# SKEAZ1284 register map
Vendor: Freescale Semiconductor, Inc.; Series: Kinetis_EA; File version: 1.6
CPU: CM0PLUS r0p0, little endian, no MPU, no FPU, VTOR, 2 interrupt priority bits
Registers are 8-bit, read-write, reset 0x0 unless marked. A register's access mark holds for its fields unless they carry their own. Offsets are from the block's base; [hi:lo] are bit positions; {n}, {i} and the like mark numbered series.

## SystemControl — System Control Registers
Base 0xE000E000; register names take the prefix SCB_
0x08 ACTLR 32-bit ro — Auxiliary Control Register,
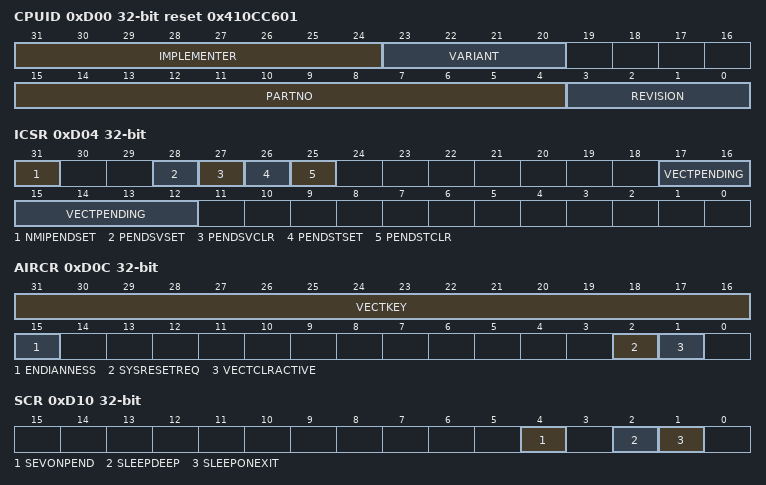
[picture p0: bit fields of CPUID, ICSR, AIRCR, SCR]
0xD00 CPUID 32-bit ro reset 0x410CC601 — CPUID Base Register
  [31:24] IMPLEMENTER — Implementer code
  [23:20] VARIANT — Indicates processor revision: 0x2 = Revision 2
  [15:4] PARTNO — Indicates part number
  [3:0] REVISION — Indicates patch release: 0x0 = Patch 0
0xD04 ICSR 32-bit — Interrupt Control and State Register
  [31] NMIPENDSET
    0=write: no effect; read: NMI exception is not pending; 1=write: changes NMI exception state to pending; read: NMI exception is pending
  [28] PENDSVSET
    0=write: no effect; read: PendSV exception is not pending; 1=write: changes PendSV exception state to pending; read: PendSV exception is pending
  [27] PENDSVCLR wo
    0=no effect; 1=removes the pending state from the PendSV exception
  [26] PENDSTSET
    0=write: no effect; read: SysTick exception is not pending; 1=write: changes SysTick exception state to pending; read: SysTick exception is pending
  [25] PENDSTCLR wo
    0=no effect; 1=removes the pending state from the SysTick exception
  [17:12] VECTPENDING ro — Exception number of the highest priority pending enabled exception
0xD08 VTOR 32-bit — Vector Table Offset Register
  [31:7] TBLOFF — Vector table base offset
0xD0C AIRCR 32-bit — Application Interrupt and Reset Control Register
  [31:16] VECTKEY — Register key
  [15] ENDIANNESS ro
    0=Little-endian; 1=Big-endian
  [2] SYSRESETREQ wo
    0=no system reset request; 1=asserts a signal to the outer system that requests a reset
  [1] VECTCLRACTIVE wo
0xD10 SCR 32-bit — System Control Register
  [4] SEVONPEND
    0=only enabled interrupts or events can wakeup the processor, disabled interrupts are excluded; 1=enabled events and all interrupts, including disabled interrupts, can wakeup the processor
  [2] SLEEPDEEP
    0=sleep; 1=deep sleep
  [1] SLEEPONEXIT
    0=do not sleep when returning to Thread mode; 1=enter sleep, or deep sleep, on return from an ISR
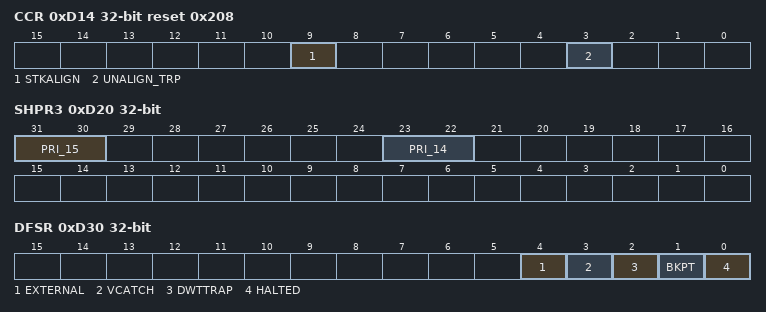
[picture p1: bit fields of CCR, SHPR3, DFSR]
0xD14 CCR 32-bit ro reset 0x208 — Configuration and Control Register
  [9] STKALIGN — Indicates stack alignment on exception entry
  [3] UNALIGN_TRP — Always reads as one, indicates that all unaligned accesses generate a HardFault
0xD1C SHPR2 32-bit — System Handler Priority Register 2
  [31:30] PRI_11 — Priority of system handler 11, SVCall
0xD20 SHPR3 32-bit — System Handler Priority Register 3
  [31:30] PRI_15 — Priority of system handler 15, SysTick exception
  [23:22] PRI_14 — Priority of system handler 14, PendSV
0xD24 SHCSR 32-bit — System Handler Control and State Register
  [15] SVCALLPENDED
    0=exception is not pending; 1=exception is pending
0xD30 DFSR 32-bit — Debug Fault Status Register
  [4] EXTERNAL
    0=No EDBGRQ debug event; 1=EDBGRQ debug event
  [3] VCATCH
    0=No Vector catch triggered; 1=Vector catch triggered
  [2] DWTTRAP
    0=No current debug events generated by the DWT; 1=At least one current debug event generated by the DWT
  [1] BKPT
    0=No current breakpoint debug event; 1=At least one current breakpoint debug event
  [0] HALTED
    0=No active halt request debug event; 1=Halt request debug event active

## SysTick — System timer
Base 0xE000E010; register names take the prefix SYST_
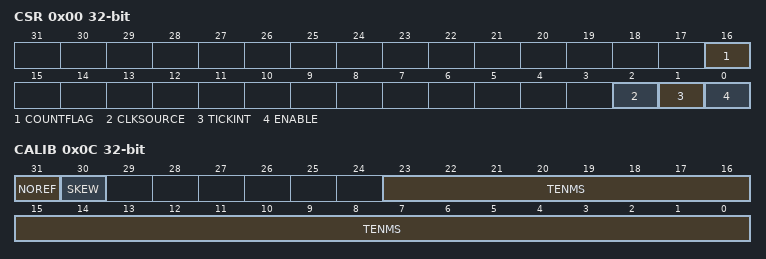
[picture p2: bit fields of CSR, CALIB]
0x00 CSR 32-bit — SysTick Control and Status Register
  [16] COUNTFLAG
  [2] CLKSOURCE
    0=external clock; 1=processor clock
  [1] TICKINT
    0=counting down to 0 does not assert the SysTick exception request; 1=counting down to 0 asserts the SysTick exception request
  [0] ENABLE
    0=counter disabled; 1=counter enabled
0x04 RVR 32-bit — SysTick Reload Value Register
  [23:0] RELOAD — Value to load into the SysTick Current Value Register when the counter reaches 0
0x08 CVR 32-bit — SysTick Current Value Register
  [23:0] CURRENT — Current value at the time the register is accessed
0x0C CALIB 32-bit ro — SysTick Calibration Value Register
  [31] NOREF
    0=The reference clock is provided; 1=The reference clock is not provided
  [30] SKEW
    0=10ms calibration value is exact; 1=10ms calibration value is inexact, because of the clock frequency
  [23:0] TENMS — Reload value to use for 10ms timing

## ROM — System ROM
Base 0xF0002000; register names take the prefix ROM_
0x00 ENTRY 32-bit ro reset not defined
0x04 TABLEMARK 32-bit ro — End of Table Marker Register
  [31:0] MARK
0xFCC SYSACCESS 32-bit ro reset 0x1 — System Access Register
0xFD0 PERIPHID{x} (x=4,5,6,7,0,1,2,3; step 0x4) 32-bit ro reset not defined — Peripheral ID Register
  [31:0] PERIPHID
{0xFF0+4i} COMPID{i} (i=0..3) 32-bit ro reset not defined — Component ID Register
  [31:0] COMPID — Component ID

## MCM — Core Platform Miscellaneous Control Module
Base 0xF0003000; register names take the prefix MCM_
0x08 PLASC 16-bit ro reset 0x7 — Crossbar Switch (AXBS) Slave Configuration
  [7:0] ASC — Each bit in the ASC field indicates whether there is a corresponding connection to the crossbar switch's slave input port.
    0=A bus slave connection to AXBS input port n is absent; 1=A bus slave connection to AXBS input port n is present
0x0A PLAMC 16-bit ro reset 0x1 — Crossbar Switch (AXBS) Master Configuration
  [7:0] AMC — Each bit in the AMC field indicates whether there is a corresponding connection to the AXBS master input port.
    0=A bus master connection to AXBS input port n is absent; 1=A bus master connection to AXBS input port n is present
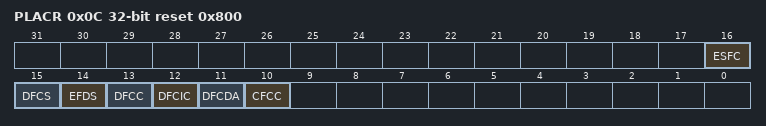
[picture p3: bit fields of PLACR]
0x0C PLACR 32-bit reset 0x800 — Platform Control Register
  [16] ESFC — Enable Stalling Flash Controller
    0=Disable stalling flash controller when flash is busy; 1=Enable stalling flash controller when flash is busy
  [15] DFCS — Disable Flash Controller Speculation
    0=Enable flash controller speculation; 1=Disable flash controller speculation
  [14] EFDS — Enable Flash Data Speculation
    0=Disable flash data speculation; 1=Enable flash data speculation
  [13] DFCC — Disable Flash Controller Cache
    0=Enable flash controller cache; 1=Disable flash controller cache
  [12] DFCIC — Disable Flash Controller Instruction Caching
    0=Enable flash controller instruction caching; 1=Disable flash controller instruction caching
  [11] DFCDA — Disable Flash Controller Data Caching
    0=Enable flash controller data caching; 1=Disable flash controller data caching
  [10] CFCC wo — Clear Flash Controller Cache
